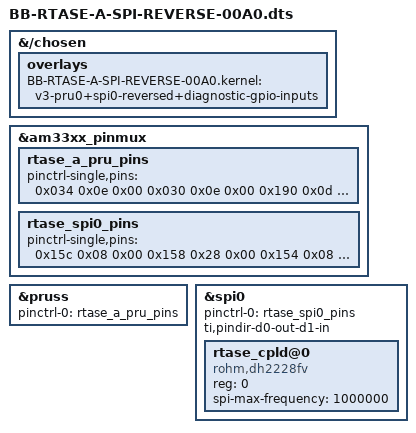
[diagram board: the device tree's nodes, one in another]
/* RTASE_V1 channel-A overlay for the temporary safe SPI direction test B. */
/dts-v1/;
/plugin/;

&{/chosen} {
	overlays {
		BB-RTASE-A-SPI-REVERSE-00A0.kernel = "v3-pru0+spi0-reversed+diagnostic-gpio-inputs";
	};
};

&am33xx_pinmux {
	rtase_a_pru_pins: rtase_a_pru_pins {
		pinctrl-single,pins = <
			0x034 0x0e 0x00
			0x030 0x0e 0x00
			0x190 0x0d 0x00
			0x024 0x27 0x00
			0x028 0x27 0x00
			0x03c 0x27 0x00
			0x038 0x27 0x00
			0x08c 0x27 0x00
		>;
	};

	rtase_spi0_pins: rtase_spi0_pins {
		pinctrl-single,pins = <
			0x15c 0x08 0x00  /* P9_17 -> SPI0_CS0 */
			/* The controller reverses D0/D1 below: D1 is therefore input and
			 * D0 is output.  Keep the PADCONF direction consistent with that
			 * controller setting; the former standard-direction values made the
			 * reverse loopback result inconclusive. */
			0x158 0x28 0x00  /* P9_18 -> SPI0_D1 input */
			0x154 0x08 0x00  /* P9_21 -> SPI0_D0 output */
			0x150 0x08 0x00  /* P9_22 -> SPI0_SCLK */
		>;
	};
};

&pruss {
	status = "okay";
	pinctrl-names = "default";
	pinctrl-0 = <&rtase_a_pru_pins>;
};

&spi0 {
	status = "okay";
	pinctrl-names = "default";
	pinctrl-0 = <&rtase_spi0_pins>;
	ti,pindir-d0-out-d1-in;

	rtase_cpld@0 {
		compatible = "rohm,dh2228fv";
		reg = <0>;
		spi-max-frequency = <1000000>;
	};
};
